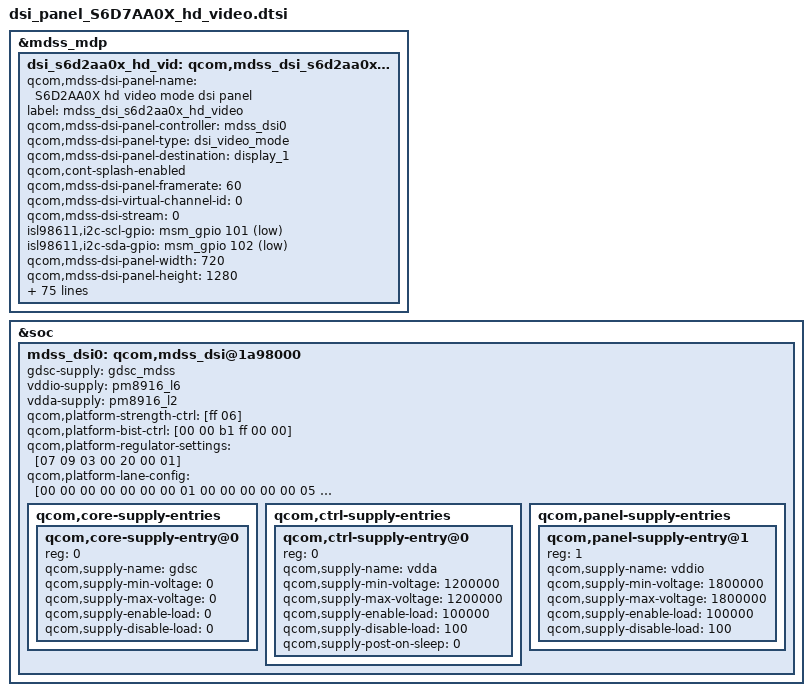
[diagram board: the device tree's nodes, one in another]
/* Copyright (c) 2013, The Linux Foundation. All rights reserved.
 *
 * This program is free software; you can redistribute it and/or modify
 * it under the terms of the GNU General Public License version 2 and
 * only version 2 as published by the Free Software Foundation.
 *
 * This program is distributed in the hope that it will be useful,
 * but WITHOUT ANY WARRANTY; without even the implied warranty of
 * MERCHANTABILITY or FITNESS FOR A PARTICULAR PURPOSE.  See the
 * GNU General Public License for more details.
 */

/*---------------------------------------------------------------------------
 * This file is autogenerated file using gcdb parser. Please do not edit it.
 * Update input XML file to add a new entry or update variable in this file
 * VERSION = "1.0"
 *---------------------------------------------------------------------------*/
&mdss_mdp {
	dsi_s6d2aa0x_hd_vid: qcom,mdss_dsi_s6d2aa0x_hd_video {
		qcom,mdss-dsi-panel-name = "S6D2AA0X hd video mode dsi panel";
		/*label = "ss_dsi_panel_S6D7AA0X62__HD";*/
		label = "mdss_dsi_s6d2aa0x_hd_video";
		qcom,mdss-dsi-panel-controller = <&mdss_dsi0>;
		qcom,mdss-dsi-panel-type = "dsi_video_mode";
		qcom,mdss-dsi-panel-destination = "display_1";
		qcom,cont-splash-enabled;
		qcom,mdss-dsi-panel-framerate = <60>;
		qcom,mdss-dsi-virtual-channel-id = <0>;
		qcom,mdss-dsi-stream = <0>;
		isl98611,i2c-scl-gpio = <&msm_gpio 101 1>;
		isl98611,i2c-sda-gpio = <&msm_gpio 102 1>;
		qcom,mdss-dsi-panel-width = <720>;
		qcom,mdss-dsi-panel-height = <1280>;
		qcom,mdss-pan-physical-width-dimension = <69>; /* <Width> real size of panel in mm */
		qcom,mdss-pan-physical-height-dimension = <124>; /*<Height> real size of panel in mm */
		qcom,mdss-dsi-lp11-init;
		qcom,mdss-dsi-init-delay-us = <20000>;
		qcom,mdss-dsi-h-front-porch = <134>;
		qcom,mdss-dsi-h-back-porch = <117>;
		qcom,mdss-dsi-h-pulse-width = <4>;
		qcom,mdss-dsi-h-sync-skew = <0>;
		qcom,mdss-dsi-v-back-porch = <6>;
		qcom,mdss-dsi-v-front-porch = <8>;
		qcom,mdss-dsi-v-pulse-width = <2>;
		qcom,mdss-dsi-h-left-border = <0>;
		qcom,mdss-dsi-h-right-border = <0>;
		qcom,mdss-dsi-v-top-border = <0>;
		qcom,mdss-dsi-v-bottom-border = <0>;
		qcom,mdss-dsi-bpp = <24>;
		qcom,mdss-dsi-color-order = <0>;
		qcom,mdss-dsi-underflow-color = <0xff>;
		qcom,mdss-dsi-border-color = <0>;
		qcom,mdss-dsi-dma-trigger = "trigger_sw";
		qcom,mdss-dsi-mdp-trigger = "none";
		qcom,mdss-dsi-bl-min-level = <1>;
		qcom,mdss-dsi-bl-max-level = <255>;
		qcom,mdss-dsi-bl-pmic-control-type = "bl_ctrl_dcs";
		qcom,mdss-dsi-lane-0-state;
		qcom,mdss-dsi-lane-1-state;
		qcom,mdss-dsi-lane-2-state;
		qcom,mdss-dsi-lane-3-state;
		qcom,mdss-dsi-bllp-eof-power-mode;
		qcom,mdss-dsi-bllp-power-mode;
		qcom,mdss-dsi-traffic-mode = "burst_mode";
		qcom,mdss-dsi-force-clk-lane-hs;
		qcom,mdss-dsi-reset-sequence = <1 20>, <0 20>, <1 100>;
		qcom,mdss-dsi-h-sync-pulse = <0>;
/*		qcom,mdss-dsi-hfp-power-mode;*/
		qcom,mdss-dsi-hbp-power-mode;
/*		qcom,mdss-dsi-hsa-power-mode;*/
		qcom,mdss-dsi-panel-timings = [87 1C 12 00 42 42 18 20 17 03 04 00];
		qcom,mdss-dsi-t-clk-pre = <0x1B>;
		qcom,mdss-dsi-t-clk-post = <0x04>;
		qcom,mdss-dsi-on-command = [
			39 01 00 00 78 00 02 11 00
			39 01 00 00 00 00 02 B0 00
			39 01 00 00 00 00 1F C9 0C 19 1C 28 32 3E 48 57 3B 43 51 5F 68 70 7F 0C 19 1C 28 32 3E 48 57 3B 43 51 5F 68 70 7F
			39 01 00 00 00 00 14 CA 01 00 00 00 00 C0 00 00 FF 00 FE B6 00 00 00 00 00 FC 00
			39 01 00 00 00 00 06 B7 78 64 10 64 AB
			39 01 00 00 00 00 12 B8 B4 40 43 49 55 62 71 82 94 A8 B9 CB DB E9 F5 FC FF
			39 01 00 00 00 00 03 B9 B4 A0
			39 01 00 00 00 00 02 BB 2E
			39 01 00 00 00 00 07 BC 01 38 04 04 00 00
			39 01 00 00 14 00 02 36 00
			39 01 00 00 00 00 02 53 26
			39 01 00 00 00 00 02 55 00
			39 01 00 00 00 00 02 5E 00
			39 01 00 00 0A 00 02 29 00
			39 01 00 00 00 00 02 B0 00
		];
		qcom,mdss-dsi-on-command-boe = [
			/* < Power Setting Sequence(1) > */
			39 01 00 00 00 00 03 F0 5A 5A		// Password1 Command
			39 01 00 00 00 00 04 E4 00 04 00	// READ ID
			05 01 00 00 14 00 02 11 00			// Display on 1
			39 01 00 00 00 00 04 B1 08 08 32	// Display Control
			39 01 00 00 00 00 02 B3 04			// Interface control
			39 01 00 00 00 00 05 BA 04 02 05 80 // Source control
			39 01 00 00 00 00 08 BB 55 55 33 33 0B 1A 04 // Power Control (1)
			39 01 00 00 00 00 02 B2 0B			// Separate(BBh)
			39 01 00 00 00 00 05 BB 33 03 33 55 // Power Control (2)
			39 01 00 00 00 00 04 BD 48 4B 00	// VGH, VGL Control
			39 01 00 00 00 00 06 F8 0A DC 18 30 0F	// PANEL_CTL7
			39 01 00 00 00 00 02 36 C0				// Scan Type
			/* <GOA Timing Sequence(2)> */
			39 01 00 00 00 00 23 B8 00 00 00 08 06 07 00 09 00 0a 00 00 00 00 00 05 04 03 11 11 11 11 11 11 11 11 11 11 11 11 11 11 11 11
			39 01 00 00 00 00 23 B9 00 00 00 08 06 07 00 09 00 0a 00 00 00 00 00 05 04 03 11 11 11 11 11 11 11 11 11 11 11 11 11 11 11 11
			/* < Gamma Setting Sequence(3)> */
			39 01 00 00 00 00 46 CA 08 FA 0A 19 22 2B 32 3D 4D
								 5A 68 7A 8A 98 A8 B2 C0 C9 D3
								 DB E3 EB F7 30 FC 31 34 37 3E
								 42 4A 56 61 6C 7D 8B 99 A9 B3
								 C0 C9 D3 DB E3 EB F7 04 FC 05
								 1F 24 30 3B 46 51 5C 68 7A 89
								 97 A8 B3 C0 C9 D3 DB E3 EB F7
			39 01 00 00 00 00 46 CB 08 FA 0A 19 22 2B 32 3D 4D
								 5A 68 7A 8A 98 A8 B2 C0 C9 D3
								 DB E3 EB F7 30 FC 31 34 37 3E
								 42 4A 56 61 6C 7D 8B 99 A9 B3
								 C0 C9 D3 DB E3 EB F7 04 FC 05
								 1F 24 30 3B 46 51 5C 68 7A 89
								 97 A8 B3 C0 C9 D3 DB E3 EB F7
			/* < Brightness Control > */
			39 01 00 00 00 00 02 53 26			// CTRL display
			39 01 00 00 00 00 02 55 00			// CABC
			39 01 00 00 00 00 02 5E 00			// CABC minimum Bright
			39 01 00 00 00 00 04 C3 0B 00 22	// LED PWM SET
			39 01 00 00 64 00 02 C1 01			// BL control mode
			/* < Display on(4) > */
			39 01 00 00 00 00 03 F0 A5 A5		// Password2 Command
			05 01 00 00 0A 00 02 29 00			// Display on 3
		];
		qcom,mdss-dsi-off-command = [
			05 01 00 00 32 00 02 28 00
			05 01 00 00 78 00 02 10 00
		];

		qcom,mdss-dsi-off-command-boe = [
			05 01 00 00 0A 00 02 28 00
			05 01 00 00 78 00 02 10 00
		];
		qcom,mdss-dsi-on-command-state = "dsi_lp_mode";
		qcom,mdss-dsi-off-command-state = "dsi_hs_mode";
/*
 * ************************************************************************************************************************************
 *
 *
 *			Below  parameters are samsung dependent thigs
 *
 *
 * ************************************************************************************************************************************
 */
		samsung,panel-vendor = "BOE";
		samsung,tft-common-support;
		samsung,level2_key_enable_tx_cmds_revA=[
			39 01 00 00 00 00 03 F0 5A 5A
		];
		samsung,level2_key_disable_tx_cmds_revA=[
			39 01 00 00 00 00 03 F0 A5 A5
		];
		samsung,packet_size_tx_cmds_revA = [
			37 01 00 00 00 00 02 07 00
		];
		/*
		 * First parameters can be changed
		 * by function of samsung_nv_read()
		 * because of that means offset of
		 * read position
		 */
		samsung,reg_read_pos_tx_cmds_revA = [
			15 01 00 00 00 00 02 B0 00
		];
		samsung,manufacture_id0_rx_cmds_revA = [06 01 00 00 00 00 01 da 03 00];
		samsung,manufacture_id1_rx_cmds_revA = [06 01 00 00 00 00 01 db 03 00];
		samsung,manufacture_id2_rx_cmds_revA = [06 01 00 00 00 00 01 dc 03 00];
/*
		* Command sets for CABC control
*/
		samsung,tft_pwm_tx_cmds_revA=[
			15 01 00 00 00 00 02 51 FF/*First command should be PWM duty change command*/
		];
		samsung,cabc_on_tx_cmds_revA = [
			39 00 00 00 05 00 02 55 01
			39 01 00 00 01 00 02 5E 0B
		];
		samsung,cabc_off_tx_cmds_revA = [
			39 00 00 00 05 00 02 55 00
			39 01 00 00 01 00 02 5E 00
		];
		/*
		* ************************************************************************************************************************
		* Scaled level to index mappings
		* ************************************************************************************************************************
		*/
		samsung,scaled_level_map_table_revA = <
		/*<idx>	  <from>  <till> <scaled_level> */
			0		0		0		0
			1		1		4		4
			2		5		6		5
			3		7		8		6
			4		9		10		7
			5		11		12		8
			6		13		14		9
			7		15		16		10
			8		17		18		11
			9		19		20		12
			10		21		22		14
			11		23		24		16
			12		25		27		18
			13		28		29		20
			14		30		32		22
			15		33		34		24
			16		35		37		26
			17		38		39		28
			18		40		42		30
			19		43		44		32
			20		45		47		34
			21		48		49		36
			22		50		52		38
			23		53		54		40
			24		55		57		42
			25		58		59		44
			26		60		62		46
			27		63		64		48
			28		65		67		50
			29		68		70		52
			30		71		72		54
			31		73		75		56
			32		76		77		58
			33		78		80		60
			34		81		82		62
			35		83		85		64
			36		86		87		66
			37		88		90		68
			38		91		92		70
			39		93		95		72
			40		96		97		74
			41		98		100		76
			42		101		102		78
			43		103		105		80
			44		106		107		82
			45		108		110		84
			46		111		112		86
			47		113		115		88
			48		116		117		90
			49		118		120		92
			50		121		122		94
			51		123		125		96
			52		126		127		98
			53		128		130		100
			54		131		133		102
			55		134		135		104
			56		136		138		107
			57		139		140		110
			58		141		143		114
			59		144		145		117
			60		146		148		121
			61		149		150		124
			62		151		153		128
			63		154		155		131
			64		156		158		135
			65		159		160		138
			66		161		163		142
			67		164		165		145
			68		166		168		149
			69		169		170		152
			70		171		173		156
			71		174		175		159
			72		176		178		163
			73		179		180		166
			74		181		183		170
			75		184		185		173
			76		186		188		177
			77		189		190		180
			78		191		193		184
			79		194		196		187
			80		197		198		190
			81		199		201		194
			82		202		203		197
			83		204		206		201
			84		207		208		203
			85		209		211		206
			86		212		213		208
			87		214		216		211
			88		217		218		213
			89		219		221		216
			90		222		223		218
			91		224		226		220
			92		227		228		222
			93		229		231		225
			94		232		233		227
			95		234		236		230
			96		237		238		232
			97		239		241		235
			98		242		243		237
			99		244		246		240
			100		247		248		242
			101		249		251		245
			102		252		253		248
			103		254		255		250
		>;
	};
};

&soc {
	mdss_dsi0: qcom,mdss_dsi@1a98000 {
		gdsc-supply = <&gdsc_mdss>;
		vddio-supply = <&pm8916_l6>;
		vdda-supply = <&pm8916_l2>;
		qcom,platform-strength-ctrl = [ff 06];
		qcom,platform-bist-ctrl = [00 00 b1 ff 00 00];
		qcom,platform-regulator-settings = [07 09 03 00 20 00 01];
		qcom,platform-lane-config = [00 00 00 00 00 00 00 01 00
			00 00 00 00 05 00 00 01 00
			00 00 00 00 0a 00 00 01 00
			00 00 00 00 0f 00 00 01 00
			00 c0 00 00 00 00 00 01 bb];
		qcom,core-supply-entries {
			#address-cells = <1>;
			#size-cells = <0>;

			qcom,core-supply-entry@0 {
				reg = <0>;
				qcom,supply-name = "gdsc";
				qcom,supply-min-voltage = <0>;
				qcom,supply-max-voltage = <0>;
				qcom,supply-enable-load = <0>;
				qcom,supply-disable-load = <0>;
			};
		};
		qcom,ctrl-supply-entries {
			#address-cells = <1>;
			#size-cells = <0>;

			qcom,ctrl-supply-entry@0 {
				reg = <0>;
				qcom,supply-name = "vdda";
				qcom,supply-min-voltage = <1200000>;
				qcom,supply-max-voltage = <1200000>;
				qcom,supply-enable-load = <100000>;
				qcom,supply-disable-load = <100>;
				qcom,supply-post-on-sleep = <0>;
			};
		};
		qcom,panel-supply-entries {
			#address-cells = <1>;
			#size-cells = <0>;

			qcom,panel-supply-entry@1 {
				reg = <1>;
				qcom,supply-name = "vddio";
				qcom,supply-min-voltage = <1800000>;
				qcom,supply-max-voltage = <1800000>;
				qcom,supply-enable-load = <100000>;
				qcom,supply-disable-load = <100>;
			};
		};
	};
};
